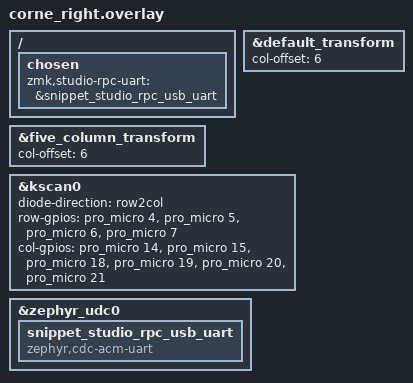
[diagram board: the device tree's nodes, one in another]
/*
 * Copyright (c) 2020 Pete Johanson
 *
 * SPDX-License-Identifier: MIT
 */

#include "corne.dtsi"

&default_transform {
    col-offset = <6>;
};

&five_column_transform {
    col-offset = <6>;
};

&kscan0 {
        diode-direction = "row2col";
        row-gpios
        = <&pro_micro 4 (GPIO_ACTIVE_HIGH)>
        , <&pro_micro 5 (GPIO_ACTIVE_HIGH)>
        , <&pro_micro 6 (GPIO_ACTIVE_HIGH)>
        , <&pro_micro 7 (GPIO_ACTIVE_HIGH)>
        ;
        col-gpios
        = <&pro_micro 14 (GPIO_ACTIVE_HIGH | GPIO_PULL_DOWN)>
        , <&pro_micro 15 (GPIO_ACTIVE_HIGH | GPIO_PULL_DOWN)>
        , <&pro_micro 18 (GPIO_ACTIVE_HIGH | GPIO_PULL_DOWN)>
        , <&pro_micro 19 (GPIO_ACTIVE_HIGH | GPIO_PULL_DOWN)>
        , <&pro_micro 20 (GPIO_ACTIVE_HIGH | GPIO_PULL_DOWN)>
        , <&pro_micro 21 (GPIO_ACTIVE_HIGH | GPIO_PULL_DOWN)>
        ;
};

/ {
    chosen {
        zmk,studio-rpc-uart = &snippet_studio_rpc_usb_uart;
    };
};

&zephyr_udc0 {
    snippet_studio_rpc_usb_uart: snippet_studio_rpc_usb_uart {
        compatible = "zephyr,cdc-acm-uart";
    };
};
